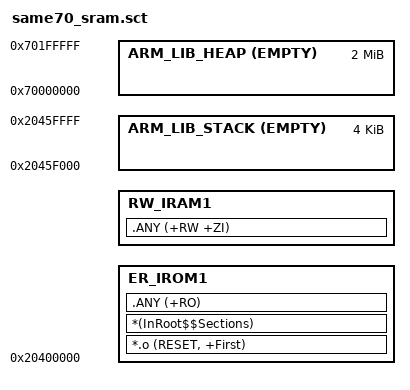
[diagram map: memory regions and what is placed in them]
;****************************************************************
;* SAME70 linker scatter file (running code from internal SRAM) *
;****************************************************************

LR_IROM1 0x20400000 0x60000
{
   ER_IROM1 0x20400000
   {
      *.o (RESET, +First)
      *(InRoot$$Sections)
      .ANY (+RO)
   }
   
   RW_IRAM1 +0
   { 
      .ANY (+RW +ZI)
   }
   
   ScatterAssert((ImageLength(ER_IROM1) + ImageLength(RW_IRAM1)) < 0x5F000)
   
   ARM_LIB_STACK 0x20460000 EMPTY -0x1000
   {
   }
   
   ARM_LIB_HEAP 0x70000000 EMPTY 0x200000
   {
   }
}
